AUTOSAR XML (schema 4-0-3)
package /ComponentTypes
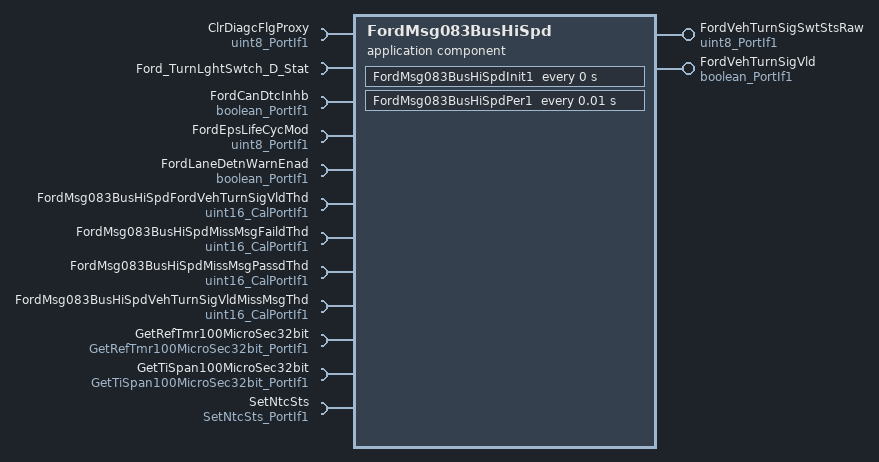
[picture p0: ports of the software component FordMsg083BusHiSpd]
  application sw component type FordMsg083BusHiSpd  # The purpose of the Ford Message 083 Bus High Speed function is to provide the Electric Power Steering system with signal values for the Lane Detection Warning function from CAN. The Ford Message 083 function w'll perform the missing message diagnostics as well asprovide a validity flag for the signal values and received message. Detailed requirements have implemented the Ford DBC file for guidance.
    provide port FordVehTurnSigSwtStsRaw: nonqueued-sender-com-spec{data-element=Val, init-value=0}, provided-interface=uint8_PortIf1  # Processed value of Vehcile Turn Signal Switch Status Raw which is used by EPS
    provide port FordVehTurnSigVld: nonqueued-sender-com-spec{data-element=Logl, init-value=0}, provided-interface=boolean_PortIf1  # This signal Check the validity of Ford Vehicle Turn Signal
    12 x require port:
      ClrDiagcFlgProxy: nonqueued-receiver-com-spec{data-element=Val, filter=data-filter-type=ALWAYS, init-value=0}, required-interface=uint8_PortIf1  # When ClrDiagcFlgProxy is True, Diagnostic test is performed
      Ford_TurnLghtSwtch_D_Stat: nonqueued-receiver-com-spec{data-element=Ford_TurnLghtSwtch_D_Stat, filter=data-filter-type=ALWAYS, init-value=0}, required-interface=Ford_TurnLghtSwtch_D_Stat  # It is a message signal which is received from CAN bus which will be pocessed. Datatype: Ford_TurnLghtSwtch_D_Stat.Elements are: 0 - "Cx0_Off", 1 - "Cx1_Left", 2 - "Cx2_Right", 3 - "Cx3_Unused_Treat_As_Off'
      FordCanDtcInhb: nonqueued-receiver-com-spec{data-element=Logl, filter=data-filter-type=ALWAYS, init-value=1}, required-interface=boolean_PortIf1  # When CAN DTC Inhibit is FALSE, Diagnostic test is performed
      FordEpsLifeCycMod: nonqueued-receiver-com-spec{data-element=Val, filter=data-filter-type=ALWAYS, init-value=0}, required-interface=uint8_PortIf1  # This signal is used to decide calibration value to FAIL the NTC
      FordLaneDetnWarnEnad: nonqueued-receiver-com-spec{data-element=Logl, filter=data-filter-type=ALWAYS, init-value=0}, required-interface=boolean_PortIf1  # This signal is set to 1 in order to set the missing NTC to pass orfail
      FordMsg083BusHiSpdFordVehTurnSigVldThd: parameter-require-com-spec{init-value=0, parameter=Val}, required-interface=uint16_CalPortIf1  # Threshold to set Ford Vehicle Turn Signal to True'
      FordMsg083BusHiSpdMissMsgFaildThd: parameter-require-com-spec{init-value=5000, parameter=Val}, required-interface=uint16_CalPortIf1  # Threshold to set the missing message NTC
      FordMsg083BusHiSpdMissMsgPassdThd: parameter-require-com-spec{init-value=0, parameter=Val}, required-interface=uint16_CalPortIf1  # Threshold to clear the missing message NTC
      FordMsg083BusHiSpdVehTurnSigVldMissMsgThd: parameter-require-com-spec{init-value=5000, parameter=Val}, required-interface=uint16_CalPortIf1  # Threshold to set Ford Vehicle Turn Signal to False when message is missing
      GetRefTmr100MicroSec32bit: client-com-spec=Oper, required-interface=GetRefTmr100MicroSec32bit_PortIf1  # It captures simulation time fromthe SimnTi value obtained at root layer of model and gives the RefTmr
      GetTiSpan100MicroSec32bit: client-com-spec=Oper, required-interface=GetTiSpan100MicroSec32bit_PortIf1  # It Captures simulation time fromSimnTi value, handles counter wrapping, and subtracts RefTmr,provides the TiSpan
      SetNtcSts: client-com-spec=Oper, required-interface=SetNtcSts_PortIf1  # Set the NTC status
    behavior FordMsg083BusHiSpd_InternalBehavior
      ar-typed-per-instance-memorys:
        9 x data, all with sw-calibration-access=READ-ONLY:
          ClrDiagcFlgProxyPrev: type=uint8  # Clear Diagc Flag Proxy
          FirstTranVldFlg: type=boolean  # This flag is used to indicate the reception of first message
          FordVehMsg083Miss: type=boolean  # Flag for missing message diagnostics, it is true when message is missing
          FordVehTurnSigSwtStsRawPrev: type=Ford_TurnLghtSwtch_D_Stat  # Previous value of Ford Vehicle Turn Signal Switch Status Raw
          FordVehTurnSigVldMissMsgRefTi: type=uint32  # Timer for misisng message will increment or reset based on the conditions
          FordVehTurnSigVldPrev: type=boolean  # Used to hold previous value of Ford Vehicle Turn Signal Valid
          FordVehTurnSigVldRefTi: type=uint32  # Timer to update Ford Vehicle Turn Signal Valid as true or false based on calibration threshold
          MissMsgFaildRefTi: type=uint32  # Timer for misisng message will increment or reset based on the message availabilty
          MissMsgPassdRefTi: type=uint32  # Timer for misisng message will increment or reset based on the message availabilty
      timing event FordMsg083BusHiSpd_InitEvent: start-on-event=FordMsg083BusHiSpdInit1, period=0
      timing event TMT_FordMsg083BusHiSpdPer1: start-on-event=FordMsg083BusHiSpdPer1, period=0.01
      port-api-options:
        enable-take-address=false, indirect-api=false, port=ClrDiagcFlgProxy
        enable-take-address=false, indirect-api=false, port=Ford_TurnLghtSwtch_D_Stat
        enable-take-address=false, indirect-api=false, port=FordCanDtcInhb
        enable-take-address=false, indirect-api=false, port=FordMsg083BusHiSpdMissMsgFaildThd
        enable-take-address=false, indirect-api=false, port=FordVehTurnSigVld
        enable-take-address=false, indirect-api=false, port=GetTiSpan100MicroSec32bit
        enable-take-address=false, indirect-api=false, port=SetNtcSts
      runnable FordMsg083BusHiSpdInit1  # Initialization Runnable
        sync call SC_GetRefTmr100MicroSec32bit_Oper: operation=GetRefTmr100MicroSec32bit.Oper, timeout=0
      runnable FordMsg083BusHiSpdPer1  # Periodic Runnable at 10 milli-seconds
        data-receive-point-by-arguments:
          5 x access:
            REC_ClrDiagcFlgProxy_Val: accessed-variable=ClrDiagcFlgProxy.Val
            REC_Ford_TurnLghtSwtch_D_Stat1_Ford_TurnLghtSwtch_D_Stat: accessed-variable=Ford_TurnLghtSwtch_D_Stat.Ford_TurnLghtSwtch_D_Stat
            REC_FordCanDtcInhb_Logl: accessed-variable=FordCanDtcInhb.Logl
            REC_FordEpsLifeCycMod_Val: accessed-variable=FordEpsLifeCycMod.Val
            REC_FordLaneDetnWarnEnad_Logl: accessed-variable=FordLaneDetnWarnEnad.Logl
        data-send-points:
          access SEND_FordVehTurnSigSwtStsRaw_Val: accessed-variable=FordVehTurnSigSwtStsRaw.Val
          access SEND_FordVehTurnSigVld_Logl: accessed-variable=FordVehTurnSigVld.Logl
        sync call SC_GetRefTmr100MicroSec32bit_Oper: operation=GetRefTmr100MicroSec32bit.Oper, timeout=0
        sync call SC_GetTiSpan100MicroSec32bit_Oper: operation=GetTiSpan100MicroSec32bit.Oper, timeout=0
        sync call SC_SetNtcSts_Oper: operation=SetNtcSts.Oper, timeout=0
  swc implementation FordMsg083BusHiSpd_Implementation: behavior=FordMsg083BusHiSpd_InternalBehavior
    code-descriptors:
      code Default: artifact-descriptors=autosar-engineering-object={short-label=Default, category=SWSRC}
